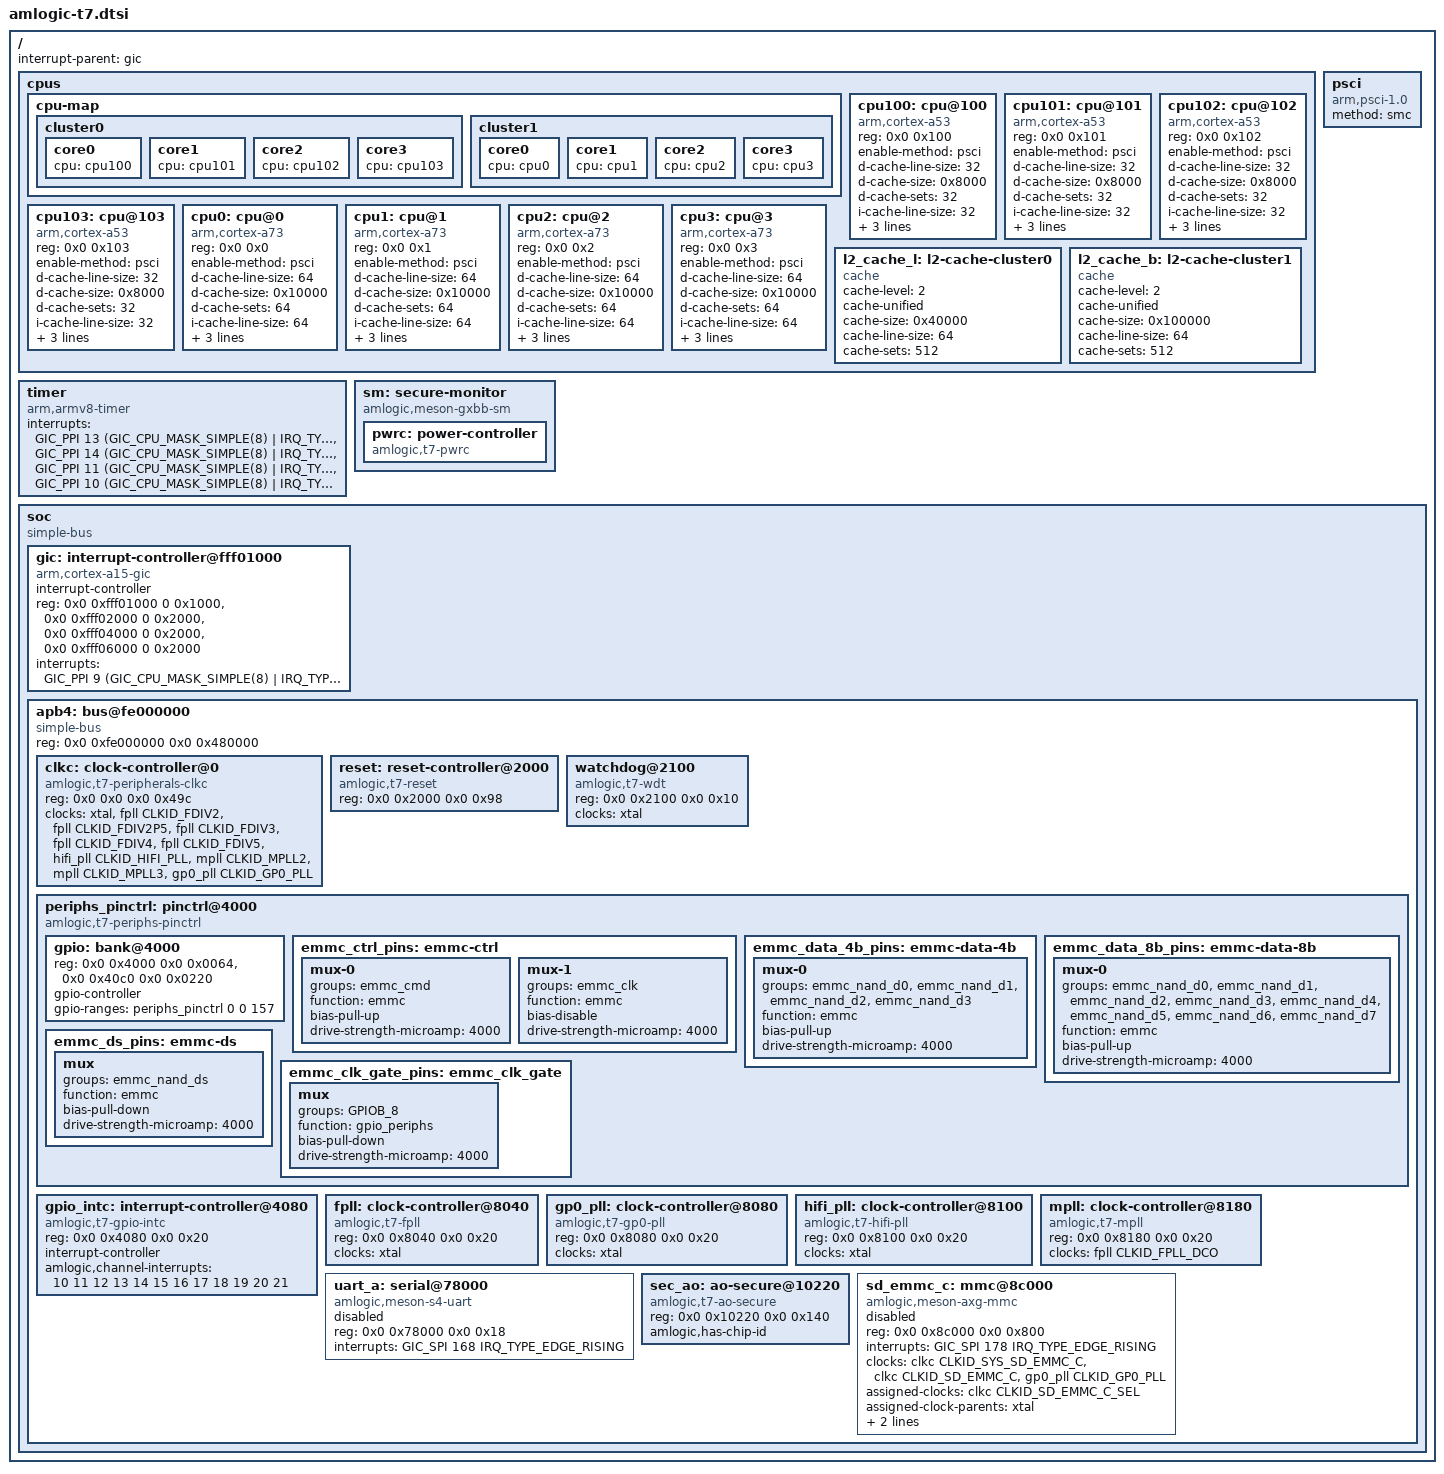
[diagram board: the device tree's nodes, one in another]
// SPDX-License-Identifier: (GPL-2.0+ OR MIT)
/*
 * Copyright (c) 2019 Amlogic, Inc. All rights reserved.
 */

#include <dt-bindings/clock/amlogic,t7-peripherals-clkc.h>
#include <dt-bindings/clock/amlogic,t7-pll-clkc.h>
#include <dt-bindings/interrupt-controller/arm-gic.h>
#include <dt-bindings/power/amlogic,t7-pwrc.h>
#include "amlogic-t7-reset.h"

/ {
	interrupt-parent = <&gic>;
	#address-cells = <2>;
	#size-cells = <2>;

	cpus {
		#address-cells = <0x2>;
		#size-cells = <0x0>;

		cpu-map {
			cluster0 {
				core0 {
					cpu = <&cpu100>;
				};
				core1 {
					cpu = <&cpu101>;
				};
				core2 {
					cpu = <&cpu102>;
				};
				core3 {
					cpu = <&cpu103>;
				};
			};

			cluster1 {
				core0 {
					cpu = <&cpu0>;
				};
				core1 {
					cpu = <&cpu1>;
				};
				core2 {
					cpu = <&cpu2>;
				};
				core3 {
					cpu = <&cpu3>;
				};
			};
		};

		cpu100: cpu@100 {
			device_type = "cpu";
			compatible = "arm,cortex-a53";
			reg = <0x0 0x100>;
			enable-method = "psci";
			d-cache-line-size = <32>;
			d-cache-size = <0x8000>;
			d-cache-sets = <32>;
			i-cache-line-size = <32>;
			i-cache-size = <0x8000>;
			i-cache-sets = <32>;
			next-level-cache = <&l2_cache_l>;
		};

		cpu101: cpu@101 {
			device_type = "cpu";
			compatible = "arm,cortex-a53";
			reg = <0x0 0x101>;
			enable-method = "psci";
			d-cache-line-size = <32>;
			d-cache-size = <0x8000>;
			d-cache-sets = <32>;
			i-cache-line-size = <32>;
			i-cache-size = <0x8000>;
			i-cache-sets = <32>;
			next-level-cache = <&l2_cache_l>;
		};

		cpu102: cpu@102 {
			device_type = "cpu";
			compatible = "arm,cortex-a53";
			reg = <0x0 0x102>;
			enable-method = "psci";
			d-cache-line-size = <32>;
			d-cache-size = <0x8000>;
			d-cache-sets = <32>;
			i-cache-line-size = <32>;
			i-cache-size = <0x8000>;
			i-cache-sets = <32>;
			next-level-cache = <&l2_cache_l>;
		};

		cpu103: cpu@103 {
			device_type = "cpu";
			compatible = "arm,cortex-a53";
			reg = <0x0 0x103>;
			enable-method = "psci";
			d-cache-line-size = <32>;
			d-cache-size = <0x8000>;
			d-cache-sets = <32>;
			i-cache-line-size = <32>;
			i-cache-size = <0x8000>;
			i-cache-sets = <32>;
			next-level-cache = <&l2_cache_l>;
		};

		cpu0: cpu@0 {
			device_type = "cpu";
			compatible = "arm,cortex-a73";
			reg = <0x0 0x0>;
			enable-method = "psci";
			d-cache-line-size = <64>;
			d-cache-size = <0x10000>;
			d-cache-sets = <64>;
			i-cache-line-size = <64>;
			i-cache-size = <0x10000>;
			i-cache-sets = <64>;
			next-level-cache = <&l2_cache_b>;
		};

		cpu1: cpu@1 {
			device_type = "cpu";
			compatible = "arm,cortex-a73";
			reg = <0x0 0x1>;
			enable-method = "psci";
			d-cache-line-size = <64>;
			d-cache-size = <0x10000>;
			d-cache-sets = <64>;
			i-cache-line-size = <64>;
			i-cache-size = <0x10000>;
			i-cache-sets = <64>;
			next-level-cache = <&l2_cache_b>;
		};

		cpu2: cpu@2 {
			device_type = "cpu";
			compatible = "arm,cortex-a73";
			reg = <0x0 0x2>;
			enable-method = "psci";
			d-cache-line-size = <64>;
			d-cache-size = <0x10000>;
			d-cache-sets = <64>;
			i-cache-line-size = <64>;
			i-cache-size = <0x10000>;
			i-cache-sets = <64>;
			next-level-cache = <&l2_cache_b>;
		};

		cpu3: cpu@3 {
			device_type = "cpu";
			compatible = "arm,cortex-a73";
			reg = <0x0 0x3>;
			enable-method = "psci";
			d-cache-line-size = <64>;
			d-cache-size = <0x10000>;
			d-cache-sets = <64>;
			i-cache-line-size = <64>;
			i-cache-size = <0x10000>;
			i-cache-sets = <64>;
			next-level-cache = <&l2_cache_b>;
		};

		l2_cache_l: l2-cache-cluster0 {
			compatible = "cache";
			cache-level = <2>;
			cache-unified;
			cache-size = <0x40000>;  /* L2. 256 KB */
			cache-line-size = <64>;
			cache-sets = <512>;
		};

		l2_cache_b: l2-cache-cluster1 {
			compatible = "cache";
			cache-level = <2>;
			cache-unified;
			cache-size = <0x100000>; /* L2. 1 Mb */
			cache-line-size = <64>;
			cache-sets = <512>;
		};
	};

	timer {
		compatible = "arm,armv8-timer";
		interrupts = <GIC_PPI 13 (GIC_CPU_MASK_SIMPLE(8) | IRQ_TYPE_LEVEL_LOW)>,
			     <GIC_PPI 14 (GIC_CPU_MASK_SIMPLE(8) | IRQ_TYPE_LEVEL_LOW)>,
			     <GIC_PPI 11 (GIC_CPU_MASK_SIMPLE(8) | IRQ_TYPE_LEVEL_LOW)>,
			     <GIC_PPI 10 (GIC_CPU_MASK_SIMPLE(8) | IRQ_TYPE_LEVEL_LOW)>;
	};

	psci {
		compatible = "arm,psci-1.0";
		method = "smc";
	};

	sm: secure-monitor {
		compatible = "amlogic,meson-gxbb-sm";

		pwrc: power-controller {
			compatible = "amlogic,t7-pwrc";
			#power-domain-cells = <1>;
		};
	};

	soc {
		compatible = "simple-bus";
		#address-cells = <2>;
		#size-cells = <2>;
		ranges;

		gic: interrupt-controller@fff01000 {
			compatible = "arm,cortex-a15-gic", "arm,cortex-a9-gic";
			#interrupt-cells = <3>;
			#address-cells = <0>;
			interrupt-controller;
			reg = <0x0 0xfff01000 0 0x1000>,
				  <0x0 0xfff02000 0 0x2000>,
				  <0x0 0xfff04000 0 0x2000>,
				  <0x0 0xfff06000 0 0x2000>;
			interrupts = <GIC_PPI 9 (GIC_CPU_MASK_SIMPLE(8) | IRQ_TYPE_LEVEL_HIGH)>;
		};

		apb4: bus@fe000000 {
			compatible = "simple-bus";
			reg = <0x0 0xfe000000 0x0 0x480000>;
			#address-cells = <2>;
			#size-cells = <2>;
			ranges = <0x0 0x0 0x0 0xfe000000 0x0 0x480000>;

			clkc: clock-controller@0 {
				compatible = "amlogic,t7-peripherals-clkc";
				reg = <0x0 0x0 0x0 0x49c>;
				#clock-cells = <1>;
				clocks = <&xtal>,
						 <&fpll CLKID_FDIV2>,
						 <&fpll CLKID_FDIV2P5>,
						 <&fpll CLKID_FDIV3>,
						 <&fpll CLKID_FDIV4>,
						 <&fpll CLKID_FDIV5>,
						 <&hifi_pll CLKID_HIFI_PLL>,
						 <&mpll CLKID_MPLL2>,
						 <&mpll CLKID_MPLL3>,
						 <&gp0_pll CLKID_GP0_PLL>;
				clock-names = "xtal", "fdiv2", "fdiv2p5", "fdiv3", "fdiv4",
							  "fdiv5", "hifi", "mpll2", "mpll3", "gp0";
			};

			reset: reset-controller@2000 {
				compatible = "amlogic,t7-reset";
				reg = <0x0 0x2000 0x0 0x98>;
				#reset-cells = <1>;
			};

			watchdog@2100 {
				compatible = "amlogic,t7-wdt";
				reg = <0x0 0x2100 0x0 0x10>;
				clocks = <&xtal>;
			};

			periphs_pinctrl: pinctrl@4000 {
				compatible = "amlogic,t7-periphs-pinctrl";
				#address-cells = <2>;
				#size-cells = <2>;
				ranges;

				gpio: bank@4000 {
					reg = <0x0 0x4000 0x0 0x0064>,
					      <0x0 0x40c0 0x0 0x0220>;
					reg-names = "mux", "gpio";
					gpio-controller;
					#gpio-cells = <2>;
					gpio-ranges = <&periphs_pinctrl 0 0 157>;
				};

				emmc_ctrl_pins: emmc-ctrl {
					mux-0 {
						groups = "emmc_cmd";
						function = "emmc";
						bias-pull-up;
						drive-strength-microamp = <4000>;
					};

					mux-1 {
						groups = "emmc_clk";
						function = "emmc";
						bias-disable;
						drive-strength-microamp = <4000>;
					};
				};

				emmc_data_4b_pins: emmc-data-4b {
					mux-0 {
						groups = "emmc_nand_d0",
								 "emmc_nand_d1",
								 "emmc_nand_d2",
								 "emmc_nand_d3";
						function = "emmc";
						bias-pull-up;
						drive-strength-microamp = <4000>;
					};
				};

				emmc_data_8b_pins: emmc-data-8b {
					mux-0 {
						groups = "emmc_nand_d0",
								 "emmc_nand_d1",
								 "emmc_nand_d2",
								 "emmc_nand_d3",
								 "emmc_nand_d4",
								 "emmc_nand_d5",
								 "emmc_nand_d6",
								 "emmc_nand_d7";
						function = "emmc";
						bias-pull-up;
						drive-strength-microamp = <4000>;
					};
				};

				emmc_ds_pins: emmc-ds {
					mux {
						groups = "emmc_nand_ds";
						function = "emmc";
						bias-pull-down;
						drive-strength-microamp = <4000>;
					};
				};

				emmc_clk_gate_pins: emmc_clk_gate {
					mux {
						groups = "GPIOB_8";
						function = "gpio_periphs";
						bias-pull-down;
						drive-strength-microamp = <4000>;
					};
				};
			};

			gpio_intc: interrupt-controller@4080 {
				compatible = "amlogic,t7-gpio-intc",
					     "amlogic,meson-gpio-intc";
				reg = <0x0 0x4080 0x0 0x20>;
				interrupt-controller;
				#interrupt-cells = <2>;
				amlogic,channel-interrupts =
					<10 11 12 13 14 15 16 17 18 19 20 21>;
			};

			fpll: clock-controller@8040 {
				compatible = "amlogic,t7-fpll";
				reg = <0x0 0x8040 0x0 0x20>;
				#clock-cells = <1>;
				clocks = <&xtal>;
				clock-names = "xtal";
			};

			gp0_pll: clock-controller@8080 {
				compatible = "amlogic,t7-gp0-pll";
				reg = <0x0 0x8080 0x0 0x20>;
				#clock-cells = <1>;
				clocks = <&xtal>;
				clock-names = "in0";
			};

			hifi_pll: clock-controller@8100 {
				compatible = "amlogic,t7-hifi-pll";
				reg = <0x0 0x8100 0x0 0x20>;
				#clock-cells = <1>;
				clocks = <&xtal>;
				clock-names = "in0";
			};

			mpll: clock-controller@8180 {
				compatible = "amlogic,t7-mpll";
				reg = <0x0 0x8180 0x0 0x20>;
				#clock-cells = <1>;
				clocks = <&fpll CLKID_FPLL_DCO>;
				clock-names = "in0";
			};

			uart_a: serial@78000 {
				compatible = "amlogic,meson-s4-uart";
				reg = <0x0 0x78000 0x0 0x18>;
				interrupts = <GIC_SPI 168 IRQ_TYPE_EDGE_RISING>;
				status = "disabled";
			};

			sec_ao: ao-secure@10220 {
				compatible = "amlogic,t7-ao-secure",
					     "amlogic,meson-gx-ao-secure",
					     "syscon";
				reg = <0x0 0x10220 0x0 0x140>;
				amlogic,has-chip-id;
			};

			sd_emmc_c: mmc@8c000{
				compatible = "amlogic,meson-axg-mmc";
				reg = <0x0 0x8c000 0x0 0x800>;
				interrupts = <GIC_SPI 178 IRQ_TYPE_EDGE_RISING>;
				status = "disabled";
				clocks = <&clkc CLKID_SYS_SD_EMMC_C>,
						 <&clkc CLKID_SD_EMMC_C>,
						 <&gp0_pll CLKID_GP0_PLL>;
				clock-names = "core", "clkin0", "clkin1";
				assigned-clocks = <&clkc CLKID_SD_EMMC_C_SEL>;
				assigned-clock-parents = <&xtal>;
				no-sdio;
				no-sd;
			};
		};

	};
};
